# GAP8 register map
Vendor: GreenWaves Technologies SAS; Series: GAP8; File version: 1.3.1
CPU: other r1p0, little endian, MPU, no FPU, I-cache, DTCM, false interrupt priority bits
Registers are 32-bit, read-write, reset 0x0 unless marked. A register's access mark holds for its fields unless they carry their own. Offsets are from the block's base; [hi:lo] are bit positions; 'fields as' and 'values as' point back to an identical list.

## cl_timer_unit — Cluster timer
Base 0x10200400
Same registers: fc_timer_unit 0x1B200400
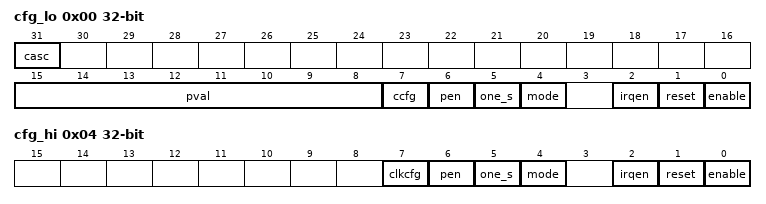
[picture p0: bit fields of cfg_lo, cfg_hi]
0x00 cfg_lo — Timer Low Configuration register.
  [31] casc — Timer low + Timer high 64bit cascaded mode configuration bitfield.
  [15:8] pval — Timer low prescaler value bitfield. Ftimer = Fclk / (1 + PRESC_VAL)
  [7] ccfg — Timer low clock source configuration bitfield
    0=FLL or FLL+Prescaler; 1=Reference clock at 32kHz
  [6] pen — Timer low prescaler enable configuration bitfield
    0=disabled (feature is disabled); 1=enabled (feature is enabled)
  [5] one_s — Timer low one shot configuration bitfield
    0=let Timer low enabled counting when compare match with CMP_LO occurs; 1=disable Timer low when compare match with CMP_LO occurs
  [4] mode — Timer low continuous mode configuration bitfield
    0=continue_mode (continue incrementing Timer low counter when compare match with CMP_LO occurs.); 1=cycle_mode (reset Timer low counter when compare match with CMP_LO occurs.)
  [2] irqen — Timer low compare match interrupt enable configuration bitfield
    values as pen
  [1] reset — Timer low counter reset command bitfield. Cleared after Timer Low reset execution.
  [0] enable — Timer low enable configuration bitfield
    values as pen
0x04 cfg_hi — Timer High Configuration register.
  [7] clkcfg — Timer high clock source configuration bitfield
    0=FLL or FLL+Prescaler; 1=Reference clock at 32kHz
  [6] pen — Timer high prescaler enable configuration bitfield
    values as cfg_lo.pen
  [5] one_s — Timer high one shot configuration bitfield
    0=let Timer high enabled counting when compare match with CMP_LO occurs; 1=disable Timer high when compare match with CMP_LO occurs
  [4] mode — Timer high continuous mode configuration bitfield
    0=continue_mode (continue incrementing Timer high counter when compare match with CMP_LO occurs.); 1=cycle_mode (reset Timer high counter when compare match with CMP_LO occurs.)
  [2] irqen — Timer high compare match interrupt enable configuration bitfield
    values as cfg_lo.pen
  [1] reset wo — Timer high counter reset command bitfield. Cleared after Timer high reset execution.
  [0] enable — Timer high enable configuration bitfield
    values as cfg_lo.pen
0x08 cnt_lo — Timer Low counter value register.
  [31:0] cnt_lo — Timer Low counter value bitfield.
0x0C cnt_hi — Timer High counter value register.
  [31:0] cnt_hi — Timer High counter value bitfield.
0x10 cmp_lo — Timer Low comparator value register.
  [31:0] cmp_lo — Timer Low comparator value bitfield.
0x14 cmp_hi — Timer High comparator value register.
  [31:0] cmp_hi — Timer High comparator value bitfield.
0x18 start_lo — Start Timer Low counting register.
  [0] strt_lo wo — Timer Low start command bitfield. When executed, CFG_LO.ENABLE is set.
0x1C start_hi — Start Timer High counting register.
  [0] strt_hi wo — Timer High start command bitfield. When executed, CFG_HI.ENABLE is set.
0x20 reset_lo — Reset Timer Low counter register.
  [0] rst_lo wo — Timer Low counter reset command bitfield. When executed, CFG_LO.RESET is set.
0x24 reset_hi — Reset Timer High counter register.
  [0] rst_hi wo — Timer High counter reset command bitfield. When executed, CFG_HI.RESET is set.

## cl_icache_ctrl — Cluster instruction cache control unit
Base 0x10201400
0x00 enable wo — Cluster instruction cache unit enable configuration register.
  [0] en — Cluster instruction cache enable configuration bitfield
    on write: 0=disabled (feature is disabled); 1=enabled (feature is enabled)
0x04 flush wo — Cluster instruction cache unit flush command register.
  [0] fl — Cluster instruction cache full flush command.
0x0C sel_flush wo — Cluster instruction cache unit selective flush command register.
  [31:0] addr — Cluster instruction cache selective flush address configuration bitfield.
